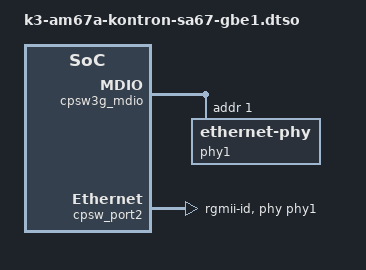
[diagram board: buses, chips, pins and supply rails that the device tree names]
// SPDX-License-Identifier: GPL-2.0-only OR MIT
/*
 * Second ethernet port GBE1.
 *
 * Copyright (c) 2025 Kontron Europe GmbH
 */

/dts-v1/;
/plugin/;

&cpsw3g_mdio {
	#address-cells = <1>;
	#size-cells = <0>;

	phy1: ethernet-phy@1 {
		reg = <1>;
	};
};

&cpsw_port2 {
	phy-connection-type = "rgmii-id";
	phy-handle = <&phy1>;
	nvmem-cells = <&base_mac_address 1>;
	nvmem-cell-names = "mac-address";
	status = "okay";
};
